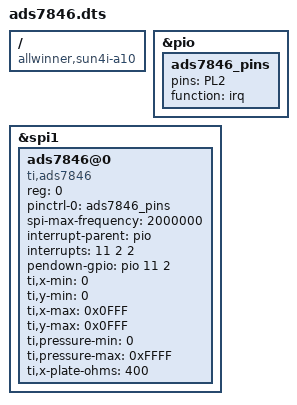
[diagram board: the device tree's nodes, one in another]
/dts-v1/;
/plugin/;

/ {
	compatible = "allwinner,sun4i-a10", "allwinner,sun7i-a20", "allwinner,sun8i-h3", "allwinner,sun50i-a64", "allwinner,sun50i-h5", "allwinner,sun50i-h6", "arm,sun50iw6p1";

	fragment@0 {
		target = <&pio>;
		__overlay__ {
			ads7846_pins: ads7846_pins {
				pins= "PL2";
				function = "irq";
           		};
		};
	};

	fragment@1 {
		target = <&spi1>;
		__overlay__ {
			#address-cells = <1>;
			#size-cells = <0>;
			status = "okay";
			ads7846@0 {
				compatible = "ti,ads7846";
				reg = <0>; /* Chip Select 0 */ // vi prøver med 1
				status = "okay";
				pinctrl-names = "default";
				pinctrl-0 = <&ads7846_pins>;
				spi-max-frequency = <2000000>;
				interrupt-parent = <&pio>;
				interrupts = <11 2 2>; /* PD24 IRQ_TYPE_EDGE_FALLING */
				pendown-gpio = <&pio 11 2 0>; /* PL3 */

				/* driver defaults, optional */
				ti,x-min = /bits/ 16 <0>;
				ti,y-min = /bits/ 16 <0>;
				ti,x-max = /bits/ 16 <0x0FFF>;
				ti,y-max = /bits/ 16 <0x0FFF>;
				ti,pressure-min = /bits/ 16 <0>;
				ti,pressure-max = /bits/ 16 <0xFFFF>;
				ti,x-plate-ohms = /bits/ 16 <400>;
			};
		};
	};
};
